# daric register map
Vendor: cramium
Registers are 32-bit, read-write, reset 0x0 unless marked. A register's access mark holds for its fields unless they carry their own. Offsets are from the block's base; [hi:lo] are bit positions; {n}, {i} and the like mark numbered series.

## SDDC
Base 0x50121000
0x00 SFR_IO — See file:///F:/code/cram-soc/soc_oss/rtl/ifsub/sddc_v0.2.sv
  [1:0] sfr_io — sfr_io read/write control register
0x04 SFR_AR — See file:///F:/code/cram-soc/soc_oss/rtl/ifsub/sddc_v0.2.sv
  [31:0] sfr_ar — sfr_ar performs action on write of value: 0x5a
0x10 CR_OCR — See file:///F:/code/cram-soc/soc_oss/rtl/ifsub/sddc_v0.2.sv
  [23:0] cr_ocr — cr_ocr read/write control register
0x14 CR_RDFFTHRES — See file:///F:/code/cram-soc/soc_oss/rtl/ifsub/sddc_v0.2.sv
  [7:0] cr_rdffthres — cr_rdffthres read/write control register
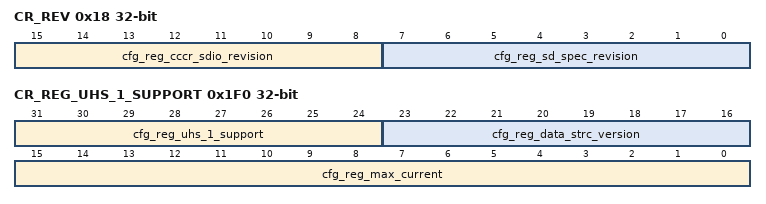
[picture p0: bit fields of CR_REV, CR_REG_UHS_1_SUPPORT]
0x18 CR_REV — See file:///F:/code/cram-soc/soc_oss/rtl/ifsub/sddc_v0.2.sv
  [15:8] cfg_reg_cccr_sdio_revision — cfg_reg_cccr_sdio_revision read/write control register
  [7:0] cfg_reg_sd_spec_revision — cfg_reg_sd_spec_revision read/write control register
0x1C CR_BACSA — See file:///F:/code/cram-soc/soc_oss/rtl/ifsub/sddc_v0.2.sv
  [17:0] cfg_base_addr_csa — cfg_base_addr_csa read/write control register
{0x20+4i} CR_BAIOFN_CFG_BASE_ADDR_IO_FUNC{i} (i=0..7) — See file:///F:/code/cram-soc/soc_oss/rtl/ifsub/sddc_v0.2.sv
  [17:0] cfg_base_addr_io_func{i} — cfg_base_addr_io_func read/write control register
{0x40+4i} CR_FNCISPTR_CFG_REG_FUNC_CIS_PTR{i} (i=0..7) — See file:///F:/code/cram-soc/soc_oss/rtl/ifsub/sddc_v0.2.sv
  [16:0] cfg_reg_func_cis_ptr{i} — cfg_reg_func_cis_ptr read/write control register
{0x60+4i} CR_FNEXTSTDCODE_CFG_REG_FUNC_EXT_STD_CODE{i} (i=0..7) — See file:///F:/code/cram-soc/soc_oss/rtl/ifsub/sddc_v0.2.sv
  [7:0] cfg_reg_func_ext_std_code{i} — cfg_reg_func_ext_std_code read/write control register
0x80 CR_WRITE_PROTECT — See file:///F:/code/cram-soc/soc_oss/rtl/ifsub/sddc_v0.2.sv
  [0] cr_write_protect — cr_write_protect read/write control register
0x84 CR_REG_DSR — See file:///F:/code/cram-soc/soc_oss/rtl/ifsub/sddc_v0.2.sv
  [15:0] cr_reg_dsr — cr_reg_dsr read/write control register
{0x88+4i} CR_REG_CID_CFG_REG_CID{i} (i=0..3) — See file:///F:/code/cram-soc/soc_oss/rtl/ifsub/sddc_v0.2.sv
  [31:0] cfg_reg_cid{i} — cr_reg_cid read/write control register
{0x98+4i} CR_REG_CSD_CFG_REG_CSD{i} (i=0..3) — See file:///F:/code/cram-soc/soc_oss/rtl/ifsub/sddc_v0.2.sv
  [31:0] cfg_reg_csd{i} — cr_reg_csd read/write control register
0xA8 CR_REG_SCR_CFG_REG_SCR0 — See file:///F:/code/cram-soc/soc_oss/rtl/ifsub/sddc_v0.2.sv
  [31:0] cfg_reg_scr0 — cr_reg_scr read/write control register
0xAC CR_REG_SCR_CFG_REG_SCR1 — See file:///F:/code/cram-soc/soc_oss/rtl/ifsub/sddc_v0.2.sv
  [31:0] cfg_reg_scr1 — cr_reg_scr read/write control register
{0xB0+4i} CR_REG_SD_STATUS_CFG_REG_SD_STATUS{i} (i=0..15) — See file:///F:/code/cram-soc/soc_oss/rtl/ifsub/sddc_v0.2.sv
  [31:0] cfg_reg_sd_status{i} — cr_reg_sd_status read/write control register
{0x100+4i} CR_BASE_ADDR_MEM_FUNC_CFG_BASE_ADDR_MEM_FUNC{i} (i=0..17) — See file:///F:/code/cram-soc/soc_oss/rtl/ifsub/sddc_v0.2.sv
  [17:0] cfg_base_addr_mem_func{i} — cfg_base_addr_mem_func read/write control register
{0x148+4i} CR_REG_FUNC_ISDIO_INTERFACE_CODE_CFG_REG_FUNC_ISDIO_INTERFACE_CODE{i} (i=0..6) — See file:///F:/code/cram-soc/soc_oss/rtl/ifsub/sddc_v0.2.sv
  [7:0] cfg_reg_func_isdio_interface_code{i} — cfg_reg_func_isdio_interface_code read/write control register
{0x168+4i} CR_REG_FUNC_MANUFACT_CODE_CFG_REG_FUNC_MANUFACT_CODE{i} (i=0..6) — See file:///F:/code/cram-soc/soc_oss/rtl/ifsub/sddc_v0.2.sv
  [15:0] cfg_reg_func_manufact_code{i} — cfg_reg_func_manufact_code read/write control register
{0x188+4i} CR_REG_FUNC_MANUFACT_INFO_CFG_REG_FUNC_MANUFACT_INFO{i} (i=0..6) — See file:///F:/code/cram-soc/soc_oss/rtl/ifsub/sddc_v0.2.sv
  [15:0] cfg_reg_func_manufact_info{i} — cfg_reg_func_manufact_info read/write control register
{0x1A8+4i} CR_REG_FUNC_ISDIO_TYPE_SUP_CODE_CFG_REG_FUNC_ISDIO_TYPE_SUP_CODE{i} (i=0..6) — See file:///F:/code/cram-soc/soc_oss/rtl/ifsub/sddc_v0.2.sv
  [7:0] cfg_reg_func_isdio_type_sup_code{i} — cfg_reg_func_isdio_type_sup_code read/write control register
{0x1C8+4i} CR_REG_FUNC_INFO_CFG_REG_FUNC_INFO{i} (i=0..6) — See file:///F:/code/cram-soc/soc_oss/rtl/ifsub/sddc_v0.2.sv
  [15:0] cfg_reg_func_info{i} — cfg_reg_func_info read/write control register
0x1F0 CR_REG_UHS_1_SUPPORT — See file:///F:/code/cram-soc/soc_oss/rtl/ifsub/sddc_v0.2.sv
  [31:24] cfg_reg_uhs_1_support — cfg_reg_uhs_1_support read/write control register
  [23:16] cfg_reg_data_strc_version — cfg_reg_data_strc_version read/write control register
  [15:0] cfg_reg_max_current — cfg_reg_max_current read/write control register
